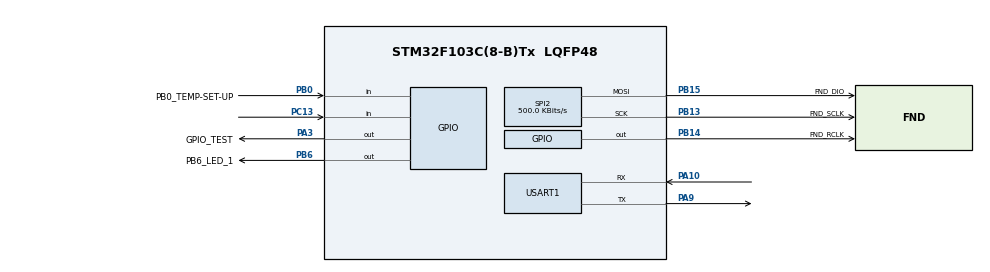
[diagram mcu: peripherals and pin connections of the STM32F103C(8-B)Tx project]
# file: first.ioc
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Mcu.Family=STM32F1
Mcu.Name=STM32F103C(8-B)Tx
Mcu.Package=LQFP48
NVIC.PriorityGroup=NVIC_PRIORITYGROUP_4
PA10.Mode=Asynchronous
PA10.Signal=USART1_RX
PA13.Mode=Serial_Wire
PA13.Signal=SYS_JTMS-SWDIO
PA14.Mode=Serial_Wire
PA14.Signal=SYS_JTCK-SWCLK
PA3.GPIO_Label=GPIO_TEST
PA3.GPIO_PuPd=GPIO_PULLUP
PA3.GPIO_Speed=GPIO_SPEED_FREQ_HIGH
PA3.PinState=GPIO_PIN_SET
PA3.Signal=GPIO_Output
PA9.Mode=Asynchronous
PA9.Signal=USART1_TX
PB0.GPIO_Label=PB0_TEMP-SET-UP
PB0.GPIO_PuPd=GPIO_PULLUP
PB0.Signal=GPIO_Input
PB13.GPIO_Label=FND_SCLK
PB13.Mode=TX_Only_Simplex_Unidirect_Master
PB13.Signal=SPI2_SCK
PB14.GPIO_Label=FND_RCLK
PB14.Signal=GPIO_Output
PB15.GPIO_Label=FND_DIO
PB15.Mode=TX_Only_Simplex_Unidirect_Master
PB15.Signal=SPI2_MOSI
PB6.GPIO_Label=PB6_LED_1
PB6.GPIO_PuPd=GPIO_PULLUP
PB6.PinState=GPIO_PIN_SET
PB6.Signal=GPIO_Output
PC13-TAMPER-RTC.GPIO_PuPd=GPIO_PULLUP
PC13-TAMPER-RTC.Signal=GPIO_Input
ProjectManager.HeapSize=0x200
ProjectManager.StackSize=0x400
ProjectManager.TargetToolchain=STM32CubeIDE
RCC.APB1Freq_Value=8000000
RCC.APB2Freq_Value=8000000
SPI2.BaudRatePrescaler=SPI_BAUDRATEPRESCALER_16
SPI2.CLKPhase=SPI_PHASE_2EDGE
SPI2.CLKPolarity=SPI_POLARITY_HIGH
SPI2.CalculateBaudRate=500.0 KBits/s
SPI2.DataSize=SPI_DATASIZE_8BIT
SPI2.Direction=SPI_DIRECTION_2LINES
SPI2.Mode=SPI_MODE_MASTER
SPI2.VirtualType=VM_MASTER
USART1.VirtualMode=VM_ASYNC
board=custom

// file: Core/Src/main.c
/* USER CODE BEGIN Header */
/**
  ******************************************************************************
  * @file           : main.c
  * @brief          : Main program body
  ******************************************************************************
  * @attention
  *
  * Copyright (c) 2026 STMicroelectronics.
  * All rights reserved.
  *
  * This software is licensed under terms that can be found in the LICENSE file
  * in the root directory of this software component.
  * If no LICENSE file comes with this software, it is provided AS-IS.
  *
  ******************************************************************************
  */
/* USER CODE END Header */
#include "main.h"
#include "fnd_controller.h"

SPI_HandleTypeDef hspi2;

UART_HandleTypeDef huart1;

void SystemClock_Config(void);
static void MX_GPIO_Init(void);
static void MX_USART1_UART_Init(void);
static void MX_SPI2_Init(void);

int main(void)
{

  /* MCU Configuration--------------------------------------------------------*/

  /* Reset of all peripherals, Initializes the Flash interface and the Systick. */
  HAL_Init();

  /* Configure the system clock */
  SystemClock_Config();

  /* Initialize all configured peripherals */
  MX_GPIO_Init();
  MX_USART1_UART_Init();
  MX_SPI2_Init();
  /* USER CODE BEGIN 2 */

  init_fnd(&hspi2);

  /* USER CODE END 2 */

  /* Infinite loop */
  /* USER CODE BEGIN WHILE */

  while (1)
  {

//	 send(0xF8);
//	 send(0b0001);

//	 HAL_GPIO_WritePin(FND_RCLK_GPIO_Port, FND_RCLK_Pin,HIGH);
//	 HAL_GPIO_WritePin(FND_RCLK_GPIO_Port, FND_RCLK_Pin, LOW);
//	 HAL_Delay(1000);

	for(int i=0; i<9999; i++) {
		digit4_replay(i, 50);
	}
    /* USER CODE END WHILE */

  }
}

void SystemClock_Config(void)
{
  RCC_OscInitTypeDef RCC_OscInitStruct = {0};
  RCC_ClkInitTypeDef RCC_ClkInitStruct = {0};

  /** Initializes the RCC Oscillators according to the specified parameters
  * in the RCC_OscInitTypeDef structure.
  */
  RCC_OscInitStruct.OscillatorType = RCC_OSCILLATORTYPE_HSI;
  RCC_OscInitStruct.HSIState = RCC_HSI_ON;
  RCC_OscInitStruct.HSICalibrationValue = RCC_HSICALIBRATION_DEFAULT;
  RCC_OscInitStruct.PLL.PLLState = RCC_PLL_NONE;
  if (HAL_RCC_OscConfig(&RCC_OscInitStruct) != HAL_OK)
  {
    Error_Handler();
  }

  /** Initializes the CPU, AHB and APB buses clocks
  */
  RCC_ClkInitStruct.ClockType = RCC_CLOCKTYPE_HCLK|RCC_CLOCKTYPE_SYSCLK
                              |RCC_CLOCKTYPE_PCLK1|RCC_CLOCKTYPE_PCLK2;
  RCC_ClkInitStruct.SYSCLKSource = RCC_SYSCLKSOURCE_HSI;
  RCC_ClkInitStruct.AHBCLKDivider = RCC_SYSCLK_DIV1;
  RCC_ClkInitStruct.APB1CLKDivider = RCC_HCLK_DIV1;
  RCC_ClkInitStruct.APB2CLKDivider = RCC_HCLK_DIV1;

  if (HAL_RCC_ClockConfig(&RCC_ClkInitStruct, FLASH_LATENCY_0) != HAL_OK)
  {
    Error_Handler();
  }
}

static void MX_SPI2_Init(void)
{

  /* SPI2 parameter configuration*/
  hspi2.Instance = SPI2;
  hspi2.Init.Mode = SPI_MODE_MASTER;
  hspi2.Init.Direction = SPI_DIRECTION_2LINES;
  hspi2.Init.DataSize = SPI_DATASIZE_8BIT;
  hspi2.Init.CLKPolarity = SPI_POLARITY_HIGH;
  hspi2.Init.CLKPhase = SPI_PHASE_2EDGE;
  hspi2.Init.NSS = SPI_NSS_SOFT;
  hspi2.Init.BaudRatePrescaler = SPI_BAUDRATEPRESCALER_16;
  hspi2.Init.FirstBit = SPI_FIRSTBIT_MSB;
  hspi2.Init.TIMode = SPI_TIMODE_DISABLE;
  hspi2.Init.CRCCalculation = SPI_CRCCALCULATION_DISABLE;
  hspi2.Init.CRCPolynomial = 10;
  if (HAL_SPI_Init(&hspi2) != HAL_OK)
  {
    Error_Handler();
  }

}

static void MX_USART1_UART_Init(void)
{

  huart1.Instance = USART1;
  huart1.Init.BaudRate = 115200;
  huart1.Init.WordLength = UART_WORDLENGTH_8B;
  huart1.Init.StopBits = UART_STOPBITS_1;
  huart1.Init.Parity = UART_PARITY_NONE;
  huart1.Init.Mode = UART_MODE_TX_RX;
  huart1.Init.HwFlowCtl = UART_HWCONTROL_NONE;
  huart1.Init.OverSampling = UART_OVERSAMPLING_16;
  if (HAL_UART_Init(&huart1) != HAL_OK)
  {
    Error_Handler();
  }

}

static void MX_GPIO_Init(void)
{
  GPIO_InitTypeDef GPIO_InitStruct = {0};

  /* GPIO Ports Clock Enable */
  __HAL_RCC_GPIOC_CLK_ENABLE();
  __HAL_RCC_GPIOA_CLK_ENABLE();
  __HAL_RCC_GPIOB_CLK_ENABLE();

  /*Configure GPIO pin Output Level */
  HAL_GPIO_WritePin(GPIO_TEST_GPIO_Port, GPIO_TEST_Pin, GPIO_PIN_SET);

  /*Configure GPIO pin Output Level */
  HAL_GPIO_WritePin(FND_RCLK_GPIO_Port, FND_RCLK_Pin, GPIO_PIN_RESET);

  /*Configure GPIO pin Output Level */
  HAL_GPIO_WritePin(PB6_LED_1_GPIO_Port, PB6_LED_1_Pin, GPIO_PIN_SET);

  /*Configure GPIO pin : PC13 */
  GPIO_InitStruct.Pin = GPIO_PIN_13;
  GPIO_InitStruct.Mode = GPIO_MODE_INPUT;
  GPIO_InitStruct.Pull = GPIO_PULLUP;
  HAL_GPIO_Init(GPIOC, &GPIO_InitStruct);

  /*Configure GPIO pin : GPIO_TEST_Pin */
  GPIO_InitStruct.Pin = GPIO_TEST_Pin;
  GPIO_InitStruct.Mode = GPIO_MODE_OUTPUT_PP;
  GPIO_InitStruct.Pull = GPIO_PULLUP;
  GPIO_InitStruct.Speed = GPIO_SPEED_FREQ_HIGH;
  HAL_GPIO_Init(GPIO_TEST_GPIO_Port, &GPIO_InitStruct);

  /*Configure GPIO pin : PB0_TEMP_SET_UP_Pin */
  GPIO_InitStruct.Pin = PB0_TEMP_SET_UP_Pin;
  GPIO_InitStruct.Mode = GPIO_MODE_INPUT;
  GPIO_InitStruct.Pull = GPIO_PULLUP;
  HAL_GPIO_Init(PB0_TEMP_SET_UP_GPIO_Port, &GPIO_InitStruct);

  /*Configure GPIO pin : FND_RCLK_Pin */
  GPIO_InitStruct.Pin = FND_RCLK_Pin;
  GPIO_InitStruct.Mode = GPIO_MODE_OUTPUT_PP;
  GPIO_InitStruct.Pull = GPIO_NOPULL;
  GPIO_InitStruct.Speed = GPIO_SPEED_FREQ_LOW;
  HAL_GPIO_Init(FND_RCLK_GPIO_Port, &GPIO_InitStruct);

  /*Configure GPIO pin : PB6_LED_1_Pin */
  GPIO_InitStruct.Pin = PB6_LED_1_Pin;
  GPIO_InitStruct.Mode = GPIO_MODE_OUTPUT_PP;
  GPIO_InitStruct.Pull = GPIO_PULLUP;
  GPIO_InitStruct.Speed = GPIO_SPEED_FREQ_LOW;
  HAL_GPIO_Init(PB6_LED_1_GPIO_Port, &GPIO_InitStruct);

}

void Error_Handler(void)
{
  /* USER CODE BEGIN Error_Handler_Debug */
  /* User can add his own implementation to report the HAL error return state */
  __disable_irq();
  while (1)
  {

	  for(int i =0; i<99; i++) {
		  digit4showZero(i);
	  }
  }
  /* USER CODE END Error_Handler_Debug */
}
